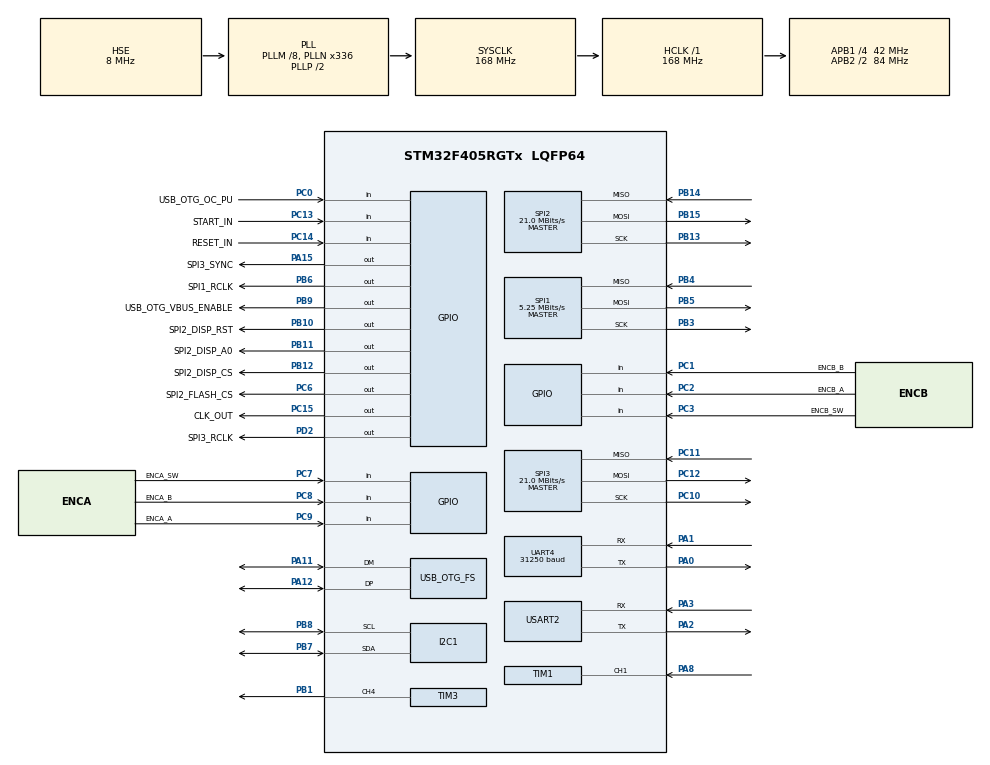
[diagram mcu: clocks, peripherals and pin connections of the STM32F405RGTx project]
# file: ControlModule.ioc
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Dma.Request0=SPI2_TX
Dma.Request1=SPI2_RX
Dma.SPI2_RX.1.Direction=DMA_PERIPH_TO_MEMORY
Dma.SPI2_RX.1.FIFOMode=DMA_FIFOMODE_DISABLE
Dma.SPI2_RX.1.Instance=DMA1_Stream3
Dma.SPI2_RX.1.MemDataAlignment=DMA_MDATAALIGN_BYTE
Dma.SPI2_RX.1.MemInc=DMA_MINC_ENABLE
Dma.SPI2_RX.1.Mode=DMA_NORMAL
Dma.SPI2_RX.1.PeriphDataAlignment=DMA_PDATAALIGN_BYTE
Dma.SPI2_RX.1.PeriphInc=DMA_PINC_DISABLE
Dma.SPI2_RX.1.Priority=DMA_PRIORITY_HIGH
Dma.SPI2_TX.0.Direction=DMA_MEMORY_TO_PERIPH
Dma.SPI2_TX.0.FIFOMode=DMA_FIFOMODE_DISABLE
Dma.SPI2_TX.0.Instance=DMA1_Stream4
Dma.SPI2_TX.0.MemDataAlignment=DMA_MDATAALIGN_BYTE
Dma.SPI2_TX.0.MemInc=DMA_MINC_ENABLE
Dma.SPI2_TX.0.Mode=DMA_NORMAL
Dma.SPI2_TX.0.PeriphDataAlignment=DMA_PDATAALIGN_BYTE
Dma.SPI2_TX.0.PeriphInc=DMA_PINC_DISABLE
Dma.SPI2_TX.0.Priority=DMA_PRIORITY_HIGH
Mcu.Family=STM32F4
Mcu.Name=STM32F405RGTx
Mcu.Package=LQFP64
NVIC.DMA1_Stream3_IRQn=true\:1\:0\:true\:false\:true\:false\:true
NVIC.DMA1_Stream4_IRQn=true\:1\:0\:true\:false\:true\:false\:true
NVIC.HASH_RNG_IRQn=true\:0\:0\:false\:false\:true\:true\:true
NVIC.OTG_FS_IRQn=true\:0\:0\:false\:false\:true\:false\:true
NVIC.PriorityGroup=NVIC_PRIORITYGROUP_2
NVIC.SPI3_IRQn=true\:0\:0\:false\:false\:true\:true\:true
NVIC.TIM1_CC_IRQn=true\:0\:0\:false\:false\:true\:true\:true
NVIC.TIM1_UP_TIM10_IRQn=true\:0\:0\:false\:false\:true\:true\:true
NVIC.TIM2_IRQn=true\:0\:0\:true\:false\:true\:true\:true
NVIC.TIM3_IRQn=true\:2\:2\:true\:false\:true\:true\:true
NVIC.UART4_IRQn=true\:0\:0\:false\:false\:true\:true\:true
PA0-WKUP.Mode=Asynchronous
PA0-WKUP.Signal=UART4_TX
PA1.Mode=Asynchronous
PA1.Signal=UART4_RX
PA10.Signal=USB_OTG_FS_ID
PA11.Mode=Device_Only
PA11.Signal=USB_OTG_FS_DM
PA12.Mode=Device_Only
PA12.Signal=USB_OTG_FS_DP
PA13.Mode=Serial_Wire
PA13.Signal=SYS_JTMS-SWDIO
PA14.Mode=Serial_Wire
PA14.Signal=SYS_JTCK-SWCLK
PA15.GPIO_Label=SPI3_SYNC
PA15.Signal=GPIO_Output
PA2.Mode=Asynchronous
PA2.Signal=USART2_TX
PA3.Mode=Asynchronous
PA3.Signal=USART2_RX
PA8.Signal=S_TIM1_CH1
PA9.Signal=USB_OTG_FS_VBUS
PB1.Signal=S_TIM3_CH4
PB10.GPIO_Label=SPI2_DISP_RST
PB10.GPIO_Speed=GPIO_SPEED_FREQ_MEDIUM
PB10.PinState=GPIO_PIN_RESET
PB10.Signal=GPIO_Output
PB11.GPIO_Label=SPI2_DISP_A0
PB11.GPIO_Speed=GPIO_SPEED_FREQ_MEDIUM
PB11.Signal=GPIO_Output
PB12.GPIO_Label=SPI2_DISP_CS
PB12.GPIO_Speed=GPIO_SPEED_FREQ_MEDIUM
PB12.PinState=GPIO_PIN_RESET
PB12.Signal=GPIO_Output
PB13.GPIO_Speed=GPIO_SPEED_FREQ_MEDIUM
PB13.Mode=Full_Duplex_Master
PB13.Signal=SPI2_SCK
PB14.GPIO_Speed=GPIO_SPEED_FREQ_MEDIUM
PB14.Mode=Full_Duplex_Master
PB14.Signal=SPI2_MISO
PB15.GPIO_Speed=GPIO_SPEED_FREQ_MEDIUM
PB15.Mode=Full_Duplex_Master
PB15.Signal=SPI2_MOSI
PB3.Mode=Full_Duplex_Master
PB3.Signal=SPI1_SCK
PB4.Mode=Full_Duplex_Master
PB4.Signal=SPI1_MISO
PB5.Mode=Full_Duplex_Master
PB5.Signal=SPI1_MOSI
PB6.GPIO_Label=SPI1_RCLK
PB6.GPIO_ModeDefaultOutputPP=GPIO_MODE_OUTPUT_OD
PB6.GPIO_Speed=GPIO_SPEED_FREQ_HIGH
PB6.PinState=GPIO_PIN_SET
PB6.Signal=GPIO_Output
PB7.Mode=I2C
PB7.Signal=I2C1_SDA
PB8.Mode=I2C
PB8.Signal=I2C1_SCL
PB9.GPIO_Label=USB_OTG_VBUS_ENABLE
PB9.Signal=GPIO_Output
PC0.GPIO_Label=USB_OTG_OC_PU
PC0.Signal=GPIO_Input
PC1.GPIO_Label=ENCB_B
PC1.GPIO_PuPd=GPIO_PULLUP
PC1.Signal=GPIO_Input
PC10.Mode=Full_Duplex_Master
PC10.Signal=SPI3_SCK
PC11.Mode=Full_Duplex_Master
PC11.Signal=SPI3_MISO
PC12.Mode=Full_Duplex_Master
PC12.Signal=SPI3_MOSI
PC13-ANTI_TAMP.GPIO_Label=START_IN
PC13-ANTI_TAMP.GPIO_PuPd=GPIO_PULLDOWN
PC13-ANTI_TAMP.Signal=GPIO_Input
PC14-OSC32_IN.GPIO_Label=RESET_IN
PC14-OSC32_IN.GPIO_PuPd=GPIO_PULLDOWN
PC14-OSC32_IN.Signal=GPIO_Input
PC15-OSC32_OUT.GPIO_Label=CLK_OUT
PC15-OSC32_OUT.GPIO_PuPd=GPIO_PULLDOWN
PC15-OSC32_OUT.Signal=GPIO_Output
PC2.GPIO_Label=ENCB_A
PC2.GPIO_PuPd=GPIO_PULLUP
PC2.Signal=GPIO_Input
PC3.GPIO_Label=ENCB_SW
PC3.GPIO_PuPd=GPIO_PULLUP
PC3.Signal=GPIO_Input
PC6.GPIO_Label=SPI2_FLASH_CS
PC6.GPIO_Speed=GPIO_SPEED_FREQ_MEDIUM
PC6.PinState=GPIO_PIN_SET
PC6.Signal=GPIO_Output
PC7.GPIO_Label=ENCA_SW
PC7.GPIO_PuPd=GPIO_PULLUP
PC7.Signal=GPIO_Input
PC8.GPIO_Label=ENCA_B
PC8.GPIO_PuPd=GPIO_PULLUP
PC8.Signal=GPIO_Input
PC9.GPIO_Label=ENCA_A
PC9.GPIO_PuPd=GPIO_PULLUP
PC9.Signal=GPIO_Input
PD2.GPIO_Label=SPI3_RCLK
PD2.GPIO_ModeDefaultOutputPP=GPIO_MODE_OUTPUT_PP
PD2.Signal=GPIO_Output
PH0-OSC_IN.Mode=HSE-External-Oscillator
PH0-OSC_IN.Signal=RCC_OSC_IN
PH1-OSC_OUT.Mode=HSE-External-Oscillator
PH1-OSC_OUT.Signal=RCC_OSC_OUT
ProjectManager.HeapSize=0x200
ProjectManager.StackSize=0x400
ProjectManager.TargetToolchain=STM32CubeIDE
RCC.48MHZClocksFreq_Value=48000000
RCC.AHBFreq_Value=168000000
RCC.APB1CLKDivider=RCC_HCLK_DIV4
RCC.APB1Freq_Value=42000000
RCC.APB1TimFreq_Value=84000000
RCC.APB2CLKDivider=RCC_HCLK_DIV2
RCC.APB2Freq_Value=84000000
RCC.APB2TimFreq_Value=168000000
RCC.CortexFreq_Value=168000000
RCC.HCLKFreq_Value=168000000
RCC.HSE_VALUE=8000000
RCC.HSI_VALUE=16000000
RCC.LSE_VALUE=32768
RCC.PLLM=8
RCC.PLLN=336
RCC.PLLQ=7
RCC.SYSCLKFreq_VALUE=168000000
RCC.SYSCLKSource=RCC_SYSCLKSOURCE_PLLCLK
RCC.VCOOutputFreq_Value=336000000
SH.S_TIM1_CH1.0=TIM1_CH1,Input_Capture1_from_TI1
SH.S_TIM3_CH4.0=TIM3_CH4,PWM Generation4 CH4
SPI1.BaudRatePrescaler=SPI_BAUDRATEPRESCALER_16
SPI1.CLKPolarity=SPI_POLARITY_HIGH
SPI1.CalculateBaudRate=5.25 MBits/s
SPI1.Direction=SPI_DIRECTION_2LINES
SPI1.Mode=SPI_MODE_MASTER
SPI1.VirtualType=VM_MASTER
SPI2.BaudRatePrescaler=SPI_BAUDRATEPRESCALER_2
SPI2.CLKPhase=SPI_PHASE_2EDGE
SPI2.CLKPolarity=SPI_POLARITY_HIGH
SPI2.CalculateBaudRate=21.0 MBits/s
SPI2.Direction=SPI_DIRECTION_2LINES
SPI2.Mode=SPI_MODE_MASTER
SPI2.VirtualType=VM_MASTER
SPI3.BaudRatePrescaler=SPI_BAUDRATEPRESCALER_2
SPI3.CalculateBaudRate=21.0 MBits/s
SPI3.Direction=SPI_DIRECTION_2LINES
SPI3.Mode=SPI_MODE_MASTER
SPI3.VirtualType=VM_MASTER
TIM1.Channel-Input_Capture1_from_TI1=TIM_CHANNEL_1
TIM1.Period=1000
TIM1.Prescaler=31
TIM2.Channel-Output\ Compare1\ No\ Output=TIM_CHANNEL_1
TIM2.Period=10000
TIM2.Prescaler=0
TIM3.Channel-PWM\ Generation4\ CH4=TIM_CHANNEL_4
TIM3.Period=1000
TIM3.Prescaler=83
TIM3.Pulse-PWM\ Generation4\ CH4=1000
UART4.BaudRate=31250
UART4.VirtualMode=Asynchronous
USART2.VirtualMode=VM_ASYNC
USB_DEVICE.CLASS_NAME_FS=AUDIO
USB_DEVICE.VirtualMode-AUDIO_FS=Audio
USB_DEVICE.VirtualModeFS=Audio_FS
USB_OTG_FS.VirtualMode=Device_Only
USB_OTG_FS.lpm_enable=DISABLE
VP_RNG_VS_RNG.Mode=RNG_Activate
VP_TIM1_VS_ClockSourceINT.Mode=Internal
VP_TIM2_VS_ClockSourceINT.Mode=Internal
VP_TIM2_VS_no_output1.Mode=Output Compare1 No Output
VP_TIM3_VS_ClockSourceINT.Mode=Internal
VP_USB_DEVICE_VS_USB_DEVICE_AUDIO_FS.Mode=AUDIO_FS
board=custom

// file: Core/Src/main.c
/* USER CODE BEGIN Header */
/**
  ******************************************************************************
  * @file           : main.c
  * @brief          : Main program body
  ******************************************************************************
  * @attention
  *
  * <h2><center>&copy; Copyright (c) 2019 STMicroelectronics.
  * All rights reserved.</center></h2>
  *
  * This software component is licensed by ST under BSD 3-Clause license,
  * the "License"; You may not use this file except in compliance with the
  * License. You may obtain a copy of the License at:
  *                        opensource.org/licenses/BSD-3-Clause
  *
  ******************************************************************************
  */
/* USER CODE END Header */

#include "main.h"
#include "usb_device.h"

I2C_HandleTypeDef hi2c1;

RNG_HandleTypeDef hrng;

SPI_HandleTypeDef hspi1;
SPI_HandleTypeDef hspi2;
SPI_HandleTypeDef hspi3;
DMA_HandleTypeDef hdma_spi2_tx;
DMA_HandleTypeDef hdma_spi2_rx;

TIM_HandleTypeDef htim1;
TIM_HandleTypeDef htim2;
TIM_HandleTypeDef htim3;

UART_HandleTypeDef huart4;
UART_HandleTypeDef huart2;

void SystemClock_Config(void);
static void MX_GPIO_Init(void);
static void MX_SPI1_Init(void);
static void MX_SPI2_Init(void);
static void MX_SPI3_Init(void);
static void MX_I2C1_Init(void);
static void MX_RNG_Init(void);
static void MX_TIM1_Init(void);
static void MX_UART4_Init(void);
static void MX_USART2_UART_Init(void);
static void MX_TIM2_Init(void);
static void MX_TIM3_Init(void);
static void MX_DMA_Init(void);

int main(void)
{

  /* MCU Configuration--------------------------------------------------------*/

  /* Reset of all peripherals, Initializes the Flash interface and the Systick. */
  HAL_Init();

  /* Configure the system clock */
  SystemClock_Config();

  /* Initialize all configured peripherals */
  MX_GPIO_Init();
  MX_SPI1_Init();
  MX_SPI2_Init();
  MX_SPI3_Init();
  MX_I2C1_Init();
  MX_RNG_Init();
  MX_TIM1_Init();
  MX_UART4_Init();
  MX_USART2_UART_Init();
  MX_TIM2_Init();
  MX_TIM3_Init();
  MX_DMA_Init();
  MX_USB_DEVICE_Init();

  /* Infinite loop */
  /* USER CODE BEGIN WHILE */
  uint8_t spi_out[2];
  spi_out[0] = 0b10101010;
  spi_out[1] = 0b10101010;

  while (1)
  {
    /* USER CODE END WHILE */

  }
}

void SystemClock_Config(void)
{
  RCC_OscInitTypeDef RCC_OscInitStruct = {0};
  RCC_ClkInitTypeDef RCC_ClkInitStruct = {0};

  /** Configure the main internal regulator output voltage
  */
  __HAL_RCC_PWR_CLK_ENABLE();
  __HAL_PWR_VOLTAGESCALING_CONFIG(PWR_REGULATOR_VOLTAGE_SCALE1);
  /** Initializes the CPU, AHB and APB busses clocks
  */
  RCC_OscInitStruct.OscillatorType = RCC_OSCILLATORTYPE_HSE;
  RCC_OscInitStruct.HSEState = RCC_HSE_ON;
  RCC_OscInitStruct.PLL.PLLState = RCC_PLL_ON;
  RCC_OscInitStruct.PLL.PLLSource = RCC_PLLSOURCE_HSE;
  RCC_OscInitStruct.PLL.PLLM = 8;
  RCC_OscInitStruct.PLL.PLLN = 336;
  RCC_OscInitStruct.PLL.PLLP = RCC_PLLP_DIV2;
  RCC_OscInitStruct.PLL.PLLQ = 7;
  if (HAL_RCC_OscConfig(&RCC_OscInitStruct) != HAL_OK)
  {
    Error_Handler();
  }
  /** Initializes the CPU, AHB and APB busses clocks
  */
  RCC_ClkInitStruct.ClockType = RCC_CLOCKTYPE_HCLK|RCC_CLOCKTYPE_SYSCLK
                              |RCC_CLOCKTYPE_PCLK1|RCC_CLOCKTYPE_PCLK2;
  RCC_ClkInitStruct.SYSCLKSource = RCC_SYSCLKSOURCE_PLLCLK;
  RCC_ClkInitStruct.AHBCLKDivider = RCC_SYSCLK_DIV1;
  RCC_ClkInitStruct.APB1CLKDivider = RCC_HCLK_DIV4;
  RCC_ClkInitStruct.APB2CLKDivider = RCC_HCLK_DIV2;

  if (HAL_RCC_ClockConfig(&RCC_ClkInitStruct, FLASH_LATENCY_5) != HAL_OK)
  {
    Error_Handler();
  }
}

static void MX_I2C1_Init(void)
{

  hi2c1.Instance = I2C1;
  hi2c1.Init.ClockSpeed = 100000;
  hi2c1.Init.DutyCycle = I2C_DUTYCYCLE_2;
  hi2c1.Init.OwnAddress1 = 0;
  hi2c1.Init.AddressingMode = I2C_ADDRESSINGMODE_7BIT;
  hi2c1.Init.DualAddressMode = I2C_DUALADDRESS_DISABLE;
  hi2c1.Init.OwnAddress2 = 0;
  hi2c1.Init.GeneralCallMode = I2C_GENERALCALL_DISABLE;
  hi2c1.Init.NoStretchMode = I2C_NOSTRETCH_DISABLE;
  if (HAL_I2C_Init(&hi2c1) != HAL_OK)
  {
    Error_Handler();
  }

}

static void MX_RNG_Init(void)
{

  hrng.Instance = RNG;
  if (HAL_RNG_Init(&hrng) != HAL_OK)
  {
    Error_Handler();
  }

}

static void MX_SPI1_Init(void)
{

  /* SPI1 parameter configuration*/
  hspi1.Instance = SPI1;
  hspi1.Init.Mode = SPI_MODE_MASTER;
  hspi1.Init.Direction = SPI_DIRECTION_2LINES;
  hspi1.Init.DataSize = SPI_DATASIZE_8BIT;
  hspi1.Init.CLKPolarity = SPI_POLARITY_HIGH;
  hspi1.Init.CLKPhase = SPI_PHASE_1EDGE;
  hspi1.Init.NSS = SPI_NSS_SOFT;
  hspi1.Init.BaudRatePrescaler = SPI_BAUDRATEPRESCALER_16;
  hspi1.Init.FirstBit = SPI_FIRSTBIT_MSB;
  hspi1.Init.TIMode = SPI_TIMODE_DISABLE;
  hspi1.Init.CRCCalculation = SPI_CRCCALCULATION_DISABLE;
  hspi1.Init.CRCPolynomial = 10;
  if (HAL_SPI_Init(&hspi1) != HAL_OK)
  {
    Error_Handler();
  }

}

static void MX_SPI2_Init(void)
{

  /* SPI2 parameter configuration*/
  hspi2.Instance = SPI2;
  hspi2.Init.Mode = SPI_MODE_MASTER;
  hspi2.Init.Direction = SPI_DIRECTION_2LINES;
  hspi2.Init.DataSize = SPI_DATASIZE_8BIT;
  hspi2.Init.CLKPolarity = SPI_POLARITY_HIGH;
  hspi2.Init.CLKPhase = SPI_PHASE_2EDGE;
  hspi2.Init.NSS = SPI_NSS_SOFT;
  hspi2.Init.BaudRatePrescaler = SPI_BAUDRATEPRESCALER_2;
  hspi2.Init.FirstBit = SPI_FIRSTBIT_MSB;
  hspi2.Init.TIMode = SPI_TIMODE_DISABLE;
  hspi2.Init.CRCCalculation = SPI_CRCCALCULATION_DISABLE;
  hspi2.Init.CRCPolynomial = 10;
  if (HAL_SPI_Init(&hspi2) != HAL_OK)
  {
    Error_Handler();
  }

}

static void MX_SPI3_Init(void)
{

  /* SPI3 parameter configuration*/
  hspi3.Instance = SPI3;
  hspi3.Init.Mode = SPI_MODE_MASTER;
  hspi3.Init.Direction = SPI_DIRECTION_2LINES;
  hspi3.Init.DataSize = SPI_DATASIZE_8BIT;
  hspi3.Init.CLKPolarity = SPI_POLARITY_LOW;
  hspi3.Init.CLKPhase = SPI_PHASE_1EDGE;
  hspi3.Init.NSS = SPI_NSS_SOFT;
  hspi3.Init.BaudRatePrescaler = SPI_BAUDRATEPRESCALER_2;
  hspi3.Init.FirstBit = SPI_FIRSTBIT_MSB;
  hspi3.Init.TIMode = SPI_TIMODE_DISABLE;
  hspi3.Init.CRCCalculation = SPI_CRCCALCULATION_DISABLE;
  hspi3.Init.CRCPolynomial = 10;
  if (HAL_SPI_Init(&hspi3) != HAL_OK)
  {
    Error_Handler();
  }

}

static void MX_TIM1_Init(void)
{

  TIM_ClockConfigTypeDef sClockSourceConfig = {0};
  TIM_MasterConfigTypeDef sMasterConfig = {0};
  TIM_IC_InitTypeDef sConfigIC = {0};

  htim1.Instance = TIM1;
  htim1.Init.Prescaler = 31;
  htim1.Init.CounterMode = TIM_COUNTERMODE_UP;
  htim1.Init.Period = 1000;
  htim1.Init.ClockDivision = TIM_CLOCKDIVISION_DIV1;
  htim1.Init.RepetitionCounter = 0;
  htim1.Init.AutoReloadPreload = TIM_AUTORELOAD_PRELOAD_DISABLE;
  if (HAL_TIM_Base_Init(&htim1) != HAL_OK)
  {
    Error_Handler();
  }
  sClockSourceConfig.ClockSource = TIM_CLOCKSOURCE_INTERNAL;
  if (HAL_TIM_ConfigClockSource(&htim1, &sClockSourceConfig) != HAL_OK)
  {
    Error_Handler();
  }
  if (HAL_TIM_IC_Init(&htim1) != HAL_OK)
  {
    Error_Handler();
  }
  sMasterConfig.MasterOutputTrigger = TIM_TRGO_RESET;
  sMasterConfig.MasterSlaveMode = TIM_MASTERSLAVEMODE_DISABLE;
  if (HAL_TIMEx_MasterConfigSynchronization(&htim1, &sMasterConfig) != HAL_OK)
  {
    Error_Handler();
  }
  sConfigIC.ICPolarity = TIM_INPUTCHANNELPOLARITY_RISING;
  sConfigIC.ICSelection = TIM_ICSELECTION_DIRECTTI;
  sConfigIC.ICPrescaler = TIM_ICPSC_DIV1;
  sConfigIC.ICFilter = 0;
  if (HAL_TIM_IC_ConfigChannel(&htim1, &sConfigIC, TIM_CHANNEL_1) != HAL_OK)
  {
    Error_Handler();
  }

}

static void MX_TIM2_Init(void)
{

  TIM_ClockConfigTypeDef sClockSourceConfig = {0};
  TIM_MasterConfigTypeDef sMasterConfig = {0};
  TIM_OC_InitTypeDef sConfigOC = {0};

  htim2.Instance = TIM2;
  htim2.Init.Prescaler = 0;
  htim2.Init.CounterMode = TIM_COUNTERMODE_UP;
  htim2.Init.Period = 10000;
  htim2.Init.ClockDivision = TIM_CLOCKDIVISION_DIV1;
  htim2.Init.AutoReloadPreload = TIM_AUTORELOAD_PRELOAD_DISABLE;
  if (HAL_TIM_Base_Init(&htim2) != HAL_OK)
  {
    Error_Handler();
  }
  sClockSourceConfig.ClockSource = TIM_CLOCKSOURCE_INTERNAL;
  if (HAL_TIM_ConfigClockSource(&htim2, &sClockSourceConfig) != HAL_OK)
  {
    Error_Handler();
  }
  if (HAL_TIM_OC_Init(&htim2) != HAL_OK)
  {
    Error_Handler();
  }
  sMasterConfig.MasterOutputTrigger = TIM_TRGO_RESET;
  sMasterConfig.MasterSlaveMode = TIM_MASTERSLAVEMODE_DISABLE;
  if (HAL_TIMEx_MasterConfigSynchronization(&htim2, &sMasterConfig) != HAL_OK)
  {
    Error_Handler();
  }
  sConfigOC.OCMode = TIM_OCMODE_TIMING;
  sConfigOC.Pulse = 0;
  sConfigOC.OCPolarity = TIM_OCPOLARITY_HIGH;
  sConfigOC.OCFastMode = TIM_OCFAST_DISABLE;
  if (HAL_TIM_OC_ConfigChannel(&htim2, &sConfigOC, TIM_CHANNEL_1) != HAL_OK)
  {
    Error_Handler();
  }

}

static void MX_TIM3_Init(void)
{

  TIM_ClockConfigTypeDef sClockSourceConfig = {0};
  TIM_MasterConfigTypeDef sMasterConfig = {0};
  TIM_OC_InitTypeDef sConfigOC = {0};

  htim3.Instance = TIM3;
  htim3.Init.Prescaler = 83;
  htim3.Init.CounterMode = TIM_COUNTERMODE_UP;
  htim3.Init.Period = 1000;
  htim3.Init.ClockDivision = TIM_CLOCKDIVISION_DIV1;
  htim3.Init.AutoReloadPreload = TIM_AUTORELOAD_PRELOAD_DISABLE;
  if (HAL_TIM_Base_Init(&htim3) != HAL_OK)
  {
    Error_Handler();
  }
  sClockSourceConfig.ClockSource = TIM_CLOCKSOURCE_INTERNAL;
  if (HAL_TIM_ConfigClockSource(&htim3, &sClockSourceConfig) != HAL_OK)
  {
    Error_Handler();
  }
  if (HAL_TIM_PWM_Init(&htim3) != HAL_OK)
  {
    Error_Handler();
  }
  sMasterConfig.MasterOutputTrigger = TIM_TRGO_RESET;
  sMasterConfig.MasterSlaveMode = TIM_MASTERSLAVEMODE_DISABLE;
  if (HAL_TIMEx_MasterConfigSynchronization(&htim3, &sMasterConfig) != HAL_OK)
  {
    Error_Handler();
  }
  sConfigOC.OCMode = TIM_OCMODE_PWM1;
  sConfigOC.Pulse = 1000;
  sConfigOC.OCPolarity = TIM_OCPOLARITY_HIGH;
  sConfigOC.OCFastMode = TIM_OCFAST_DISABLE;
  if (HAL_TIM_PWM_ConfigChannel(&htim3, &sConfigOC, TIM_CHANNEL_4) != HAL_OK)
  {
    Error_Handler();
  }
  HAL_TIM_MspPostInit(&htim3);

}

static void MX_UART4_Init(void)
{

  huart4.Instance = UART4;
  huart4.Init.BaudRate = 31250;
  huart4.Init.WordLength = UART_WORDLENGTH_8B;
  huart4.Init.StopBits = UART_STOPBITS_1;
  huart4.Init.Parity = UART_PARITY_NONE;
  huart4.Init.Mode = UART_MODE_TX_RX;
  huart4.Init.HwFlowCtl = UART_HWCONTROL_NONE;
  huart4.Init.OverSampling = UART_OVERSAMPLING_16;
  if (HAL_UART_Init(&huart4) != HAL_OK)
  {
    Error_Handler();
  }

}

static void MX_USART2_UART_Init(void)
{

  huart2.Instance = USART2;
  huart2.Init.BaudRate = 115200;
  huart2.Init.WordLength = UART_WORDLENGTH_8B;
  huart2.Init.StopBits = UART_STOPBITS_1;
  huart2.Init.Parity = UART_PARITY_NONE;
  huart2.Init.Mode = UART_MODE_TX_RX;
  huart2.Init.HwFlowCtl = UART_HWCONTROL_NONE;
  huart2.Init.OverSampling = UART_OVERSAMPLING_16;
  if (HAL_UART_Init(&huart2) != HAL_OK)
  {
    Error_Handler();
  }

}

static void MX_DMA_Init(void)
{

  /* DMA controller clock enable */
  __HAL_RCC_DMA1_CLK_ENABLE();

  /* DMA interrupt init */
  /* DMA1_Stream3_IRQn interrupt configuration */
  HAL_NVIC_SetPriority(DMA1_Stream3_IRQn, 1, 0);
  HAL_NVIC_EnableIRQ(DMA1_Stream3_IRQn);
  /* DMA1_Stream4_IRQn interrupt configuration */
  HAL_NVIC_SetPriority(DMA1_Stream4_IRQn, 1, 0);
  HAL_NVIC_EnableIRQ(DMA1_Stream4_IRQn);

}

static void MX_GPIO_Init(void)
{
  GPIO_InitTypeDef GPIO_InitStruct = {0};

  /* GPIO Ports Clock Enable */
  __HAL_RCC_GPIOC_CLK_ENABLE();
  __HAL_RCC_GPIOH_CLK_ENABLE();
  __HAL_RCC_GPIOA_CLK_ENABLE();
  __HAL_RCC_GPIOB_CLK_ENABLE();
  __HAL_RCC_GPIOD_CLK_ENABLE();

  /*Configure GPIO pin Output Level */
  HAL_GPIO_WritePin(CLK_OUT_GPIO_Port, CLK_OUT_Pin, GPIO_PIN_RESET);

  /*Configure GPIO pin Output Level */
  HAL_GPIO_WritePin(GPIOB, SPI2_DISP_RST_Pin|SPI2_DISP_A0_Pin|SPI2_DISP_CS_Pin|USB_OTG_VBUS_ENABLE_Pin, GPIO_PIN_RESET);

  /*Configure GPIO pin Output Level */
  HAL_GPIO_WritePin(SPI2_FLASH_CS_GPIO_Port, SPI2_FLASH_CS_Pin, GPIO_PIN_SET);

  /*Configure GPIO pin Output Level */
  HAL_GPIO_WritePin(SPI3_SYNC_GPIO_Port, SPI3_SYNC_Pin, GPIO_PIN_RESET);

  /*Configure GPIO pin Output Level */
  HAL_GPIO_WritePin(SPI3_RCLK_GPIO_Port, SPI3_RCLK_Pin, GPIO_PIN_RESET);

  /*Configure GPIO pin Output Level */
  HAL_GPIO_WritePin(SPI1_RCLK_GPIO_Port, SPI1_RCLK_Pin, GPIO_PIN_SET);

  /*Configure GPIO pins : START_IN_Pin RESET_IN_Pin */
  GPIO_InitStruct.Pin = START_IN_Pin|RESET_IN_Pin;
  GPIO_InitStruct.Mode = GPIO_MODE_INPUT;
  GPIO_InitStruct.Pull = GPIO_PULLDOWN;
  HAL_GPIO_Init(GPIOC, &GPIO_InitStruct);

  /*Configure GPIO pin : CLK_OUT_Pin */
  GPIO_InitStruct.Pin = CLK_OUT_Pin;
  GPIO_InitStruct.Mode = GPIO_MODE_OUTPUT_PP;
  GPIO_InitStruct.Pull = GPIO_PULLDOWN;
  GPIO_InitStruct.Speed = GPIO_SPEED_FREQ_LOW;
  HAL_GPIO_Init(CLK_OUT_GPIO_Port, &GPIO_InitStruct);

  /*Configure GPIO pin : USB_OTG_OC_PU_Pin */
  GPIO_InitStruct.Pin = USB_OTG_OC_PU_Pin;
  GPIO_InitStruct.Mode = GPIO_MODE_INPUT;
  GPIO_InitStruct.Pull = GPIO_NOPULL;
  HAL_GPIO_Init(USB_OTG_OC_PU_GPIO_Port, &GPIO_InitStruct);

  /*Configure GPIO pins : ENCB_B_Pin ENCB_A_Pin ENCB_SW_Pin ENCA_SW_Pin
                           ENCA_B_Pin ENCA_A_Pin */
  GPIO_InitStruct.Pin = ENCB_B_Pin|ENCB_A_Pin|ENCB_SW_Pin|ENCA_SW_Pin
                          |ENCA_B_Pin|ENCA_A_Pin;
  GPIO_InitStruct.Mode = GPIO_MODE_INPUT;
  GPIO_InitStruct.Pull = GPIO_PULLUP;
  HAL_GPIO_Init(GPIOC, &GPIO_InitStruct);

  /*Configure GPIO pins : SPI2_DISP_RST_Pin SPI2_DISP_A0_Pin SPI2_DISP_CS_Pin */
  GPIO_InitStruct.Pin = SPI2_DISP_RST_Pin|SPI2_DISP_A0_Pin|SPI2_DISP_CS_Pin;
  GPIO_InitStruct.Mode = GPIO_MODE_OUTPUT_PP;
  GPIO_InitStruct.Pull = GPIO_NOPULL;
  GPIO_InitStruct.Speed = GPIO_SPEED_FREQ_MEDIUM;
  HAL_GPIO_Init(GPIOB, &GPIO_InitStruct);

  /*Configure GPIO pin : SPI2_FLASH_CS_Pin */
  GPIO_InitStruct.Pin = SPI2_FLASH_CS_Pin;
  GPIO_InitStruct.Mode = GPIO_MODE_OUTPUT_PP;
  GPIO_InitStruct.Pull = GPIO_NOPULL;
  GPIO_InitStruct.Speed = GPIO_SPEED_FREQ_MEDIUM;
  HAL_GPIO_Init(SPI2_FLASH_CS_GPIO_Port, &GPIO_InitStruct);

  /*Configure GPIO pin : SPI3_SYNC_Pin */
  GPIO_InitStruct.Pin = SPI3_SYNC_Pin;
  GPIO_InitStruct.Mode = GPIO_MODE_OUTPUT_PP;
  GPIO_InitStruct.Pull = GPIO_NOPULL;
  GPIO_InitStruct.Speed = GPIO_SPEED_FREQ_LOW;
  HAL_GPIO_Init(SPI3_SYNC_GPIO_Port, &GPIO_InitStruct);

  /*Configure GPIO pin : SPI3_RCLK_Pin */
  GPIO_InitStruct.Pin = SPI3_RCLK_Pin;
  GPIO_InitStruct.Mode = GPIO_MODE_OUTPUT_PP;
  GPIO_InitStruct.Pull = GPIO_NOPULL;
  GPIO_InitStruct.Speed = GPIO_SPEED_FREQ_LOW;
  HAL_GPIO_Init(SPI3_RCLK_GPIO_Port, &GPIO_InitStruct);

  /*Configure GPIO pin : SPI1_RCLK_Pin */
  GPIO_InitStruct.Pin = SPI1_RCLK_Pin;
  GPIO_InitStruct.Mode = GPIO_MODE_OUTPUT_OD;
  GPIO_InitStruct.Pull = GPIO_NOPULL;
  GPIO_InitStruct.Speed = GPIO_SPEED_FREQ_HIGH;
  HAL_GPIO_Init(SPI1_RCLK_GPIO_Port, &GPIO_InitStruct);

  /*Configure GPIO pin : USB_OTG_VBUS_ENABLE_Pin */
  GPIO_InitStruct.Pin = USB_OTG_VBUS_ENABLE_Pin;
  GPIO_InitStruct.Mode = GPIO_MODE_OUTPUT_PP;
  GPIO_InitStruct.Pull = GPIO_NOPULL;
  GPIO_InitStruct.Speed = GPIO_SPEED_FREQ_LOW;
  HAL_GPIO_Init(USB_OTG_VBUS_ENABLE_GPIO_Port, &GPIO_InitStruct);

}

void Error_Handler(void)
{
}

/************************ (C) COPYRIGHT STMicroelectronics *****END OF FILE****/
